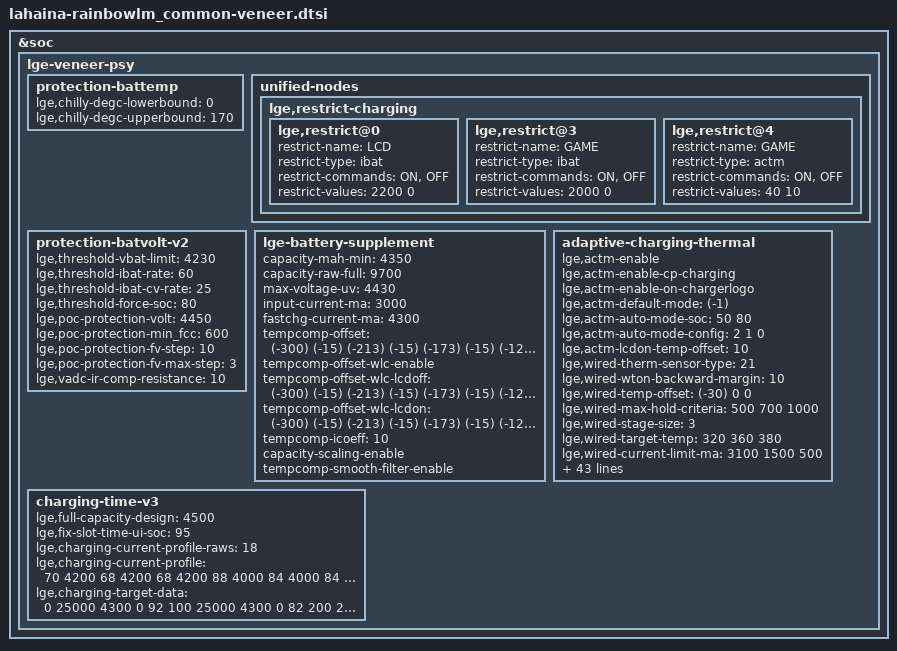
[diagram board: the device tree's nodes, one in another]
&soc {
	lge-veneer-psy {
		protection-battemp {
			lge,chilly-degc-lowerbound = <0>;
			lge,chilly-degc-upperbound = <170>;
		};

		unified-nodes {
			lge,restrict-charging {
				lge,restrict@0 {
					restrict-name = "LCD";
					restrict-type = "ibat";
					restrict-commands = "ON", "OFF";
					restrict-values = <2200      0>;
				};
				lge,restrict@3 {
					restrict-name = "GAME";
					restrict-type = "ibat";
					restrict-commands = "ON", "OFF";
					restrict-values = <2000      0>;
				};
				lge,restrict@4 {
					restrict-name = "GAME";
					restrict-type = "actm";
					restrict-commands = "ON", "OFF";
					restrict-values = <  40     10>;
				};
			};
		};

		/* it's for direct battery cell voltage sensing */
		protection-batvolt-v2 {
			lge,threshold-vbat-limit = <4230>;
			lge,threshold-ibat-rate = <60>;	// means 0.6C rate
			// the current to enter cv mode should be
			//			set to 600mA due to protection ic(4.45V).
			//			set to 1000mA due to protection ic(4.46V).
			lge,threshold-ibat-cv-rate = <25>;       // means 0.25C = 4350 * 0.23 = 1087mA
			lge,threshold-force-soc = <80>;          // %, set to 4.45V at ui soc 70%@ATL, 80%@LGC

			lge,poc-protection-volt = <4450>;
			lge,poc-protection-min_fcc = <600>;      // mA, fcc should be over cut-off current to enter termination.
			lge,poc-protection-fv-step = <10>;       // mV, if fcc is under min fcc, fv step down by 10mV.
			lge,poc-protection-fv-max-step = <3>;    // max count to step down.
			lge,vadc-ir-comp-resistance = <10>;       // mohm, compensated vadc for battery pack spec.
		};

		lge-battery-supplement {
			capacity-mah-min = <4350>;
			capacity-raw-full = <9700>;
			max-voltage-uv = <4430>;
			input-current-ma = <3000>;
			fastchg-current-ma = <4300>;

			/* format : (temp index) (temp delta) */
			tempcomp-offset = <
					(-300) (-15)
					(-213) (-15)
					(-173) (-15)
					(-126) (-15)
					( -75) (-12)
					( -23) (-12)
					( -10) (-13)
					27  (-12)
					73  (-15)
					117  (-10)
					162  (-9)
					208  (-9)
					254  (-8)
					303  (-7)
					354  (-8)
					408  (-8)
					461  (-8)
					512  (-8)
					561  (-8)
					608  (-8)
					647     4
					700     8
					730    12
					750    16
					800    20
			>;

			tempcomp-offset-wlc-enable;
			tempcomp-offset-wlc-lcdoff = <
					(-300) (-15)
					(-213) (-15)
					(-173) (-15)
					(-126) (-15)
					( -75) (-12)
					( -23) (-12)
					( -10) (-13)
					27  (-12)
					73  (-15)
					117  (-10)
					162  (-9)
					208  (-3)
					254     6
					303    30
					354    30
					408    38
					461    48
					512    11
					561    11
					608    11
					647     4
					700     8
					730    12
					750    16
					800    20
			>;

			tempcomp-offset-wlc-lcdon = <
					(-300) (-15)
					(-213) (-15)
					(-173) (-15)
					(-126) (-15)
					( -75) (-12)
					( -23) (-12)
					( -10) (-13)
					27  (-12)
					73  (-15)
					117  (-10)
					162  (-9)
					208  (-3)
					254     6
					303    30
					354    30
					408    38
					461    48
					512    11
					561    11
					608    11
					647     4
					700     8
					730    12
					750    16
					800    20
			>;

			tempcomp-icoeff = <10>;
			capacity-scaling-enable;
			tempcomp-smooth-filter-enable;
		};

		adaptive-charging-thermal {
			lge,actm-enable;
			lge,actm-enable-cp-charging;                    // whether cp charging is supported.
			lge,actm-enable-on-chargerlogo;                 // the actm operates charging first mode in chargerlogo
			lge,actm-default-mode = <(-1)>;                 // 0-thermal first, 1-balanced, 2-charging first, 3-auto
			/*  actm auto mode description
			 *                     48%            77%
			 *    2-charging first  |  1-balacned  |  0-thermal first */
			lge,actm-auto-mode-soc = <50 80>;               // those values are raw soc.
			lge,actm-auto-mode-config = <2 1 0>;            // <2 1 0> means actm mode
			lge,actm-lcdon-temp-offset = <10>;              // unit: 0.1 degree

			lge,wired-therm-sensor-type = <21>;             // bit(0)-BATT, bit(1)-VTS, Two Digit -> <$(LCDON)$(LCDOFF)>
			lge,wired-wton-backward-margin = <10>;          // temp margin when it transit from WARM to NORM.
			lge,wired-temp-offset = <(-30) 0 0>;            // thermal first, balanced, charging first
			lge,wired-max-hold-criteria = <500 700 1000>;   // allow rising 1 degree per 20/14/10/min
			lge,wired-stage-size = <3>;
			lge,wired-target-temp = <320 360 380>;
			lge,wired-current-limit-ma = <3100 1500 500>;   // 0-normal, 1-warm, 2-hot
			lge,wired-curr-cp-limit-ma = <4300 3200>;       // extension of lge,wired-current-limit-ma
			                                                // 0-normal & pps, 1-normal & qc3.0
			lge,wired-max-fcc-ma = <4300 3200 3100>;        // 0-pps ta, 1- qc3.0 ta, 2-qc2.0 ta
			lge,wired-current-step-size = <3>;
			lge,wired-current-step-temp = <5 15 30>;
			lge,wired-current-step-ma = <100 200 400>;
			lge,wired-timer-ms = <60000>;

			/* wired sidecar */
			lge,wired-sidecar-enable = <0 0 1>;             // <Thermal first, balanced, charging first>
			lge,wired-sidecar-therm-enter-temp = <380 400>;     // <LCD_OFF, LCD_ON>
			lge,wired-sidecar-therm-exit-temp = <370 390>;      // <LCD_OFF, LCD_ON>
			lge,wired-sidecar-therm-min-current = <1000 500>;   // <LCD_OFF, LCD_ON>
			lge,wired-sidecar-bal-enter-temp = <380 400>;       // <LCD_OFF, LCD_ON>
			lge,wired-sidecar-bal-exit-temp = <370 390>;        // <LCD_OFF, LCD_ON>
			lge,wired-sidecar-bal-min-current = <1000 500>;     // <LCD_OFF, LCD_ON>
			lge,wired-sidecar-chg-enter-temp = <380 400>;       // <LCD_OFF, LCD_ON>
			lge,wired-sidecar-chg-exit-temp = <370 390>;        // <LCD_OFF, LCD_ON>
			lge,wired-sidecar-chg-min-current = <1000 500>;     // <LCD_OFF, LCD_ON>

			lge,wireless-therm-sensor-type = <33>;          // bit(0)-BATT, bit(1)-VTS, Two Digit -> <$(LCDON)$(LCDOFF)>
			lge,wireless-wton-backward-margin = <0>;        // temp margin when it transit from WARM to NORM.
			lge,wireless-temp-offset = <(-30) 0 0>;         // thermal first, balanced, charging first
			lge,wireless-max-hold-criteria = <250 333 500>; // allow rising 1 degree per 40/30/20min
			lge,wireless-stage-size = <3>;
			lge,wireless-target-temp = <290 380 420>;
			lge,wireless-epp-power-limit-mw = <6300 4050 2750>;
			lge,wireless-bpp-power-limit-mw = <4400 3850 2750>;
			lge,wireless-15w-max-power-mw = <0 0 7200>; // <Thermal first, balanced, charging first>
			lge,wireless-power-step-size = <3>;
			lge,wireless-power-step-temp = <5 15 30>;
			lge,wireless-epp-power-step-mw = <450 900 1350>;
			lge,wireless-bpp-power-step-mw = <275 550 825>;
			lge,wireless-timer-ms = <60000>;

			/* wireless sidecar */
			lge,wireless-sidecar-enable = <0 0 1>;          // <Thermal first, balanced, charging first>
			lge,wireless-sidecar-therm-enter-temp = <420 420>;  // <LCD_OFF, LCD_ON>
			lge,wireless-sidecar-therm-exit-temp = <400 400>;   // <LCD_OFF, LCD_ON>
			lge,wireless-sidecar-therm-min-power = <3000 3000>; // <LCD_OFF, LCD_ON>
			lge,wireless-sidecar-bal-enter-temp = <420 420>;    // <LCD_OFF, LCD_ON>
			lge,wireless-sidecar-bal-exit-temp = <400 400>;     // <LCD_OFF, LCD_ON>
			lge,wireless-sidecar-bal-min-power = <3000 3000>;   // <LCD_OFF, LCD_ON>
			lge,wireless-sidecar-chg-enter-temp = <420 420>;    // <LCD_OFF, LCD_ON>
			lge,wireless-sidecar-chg-exit-temp = <400 400>;     // <LCD_OFF, LCD_ON>
			lge,wireless-sidecar-chg-min-power = <3000 3000>;   // <LCD_OFF, LCD_ON>
		};

		charging-time-v3 {
			lge,full-capacity-design = <4500>;
			lge,fix-slot-time-ui-soc = <95>;

			lge,charging-current-profile-raws = <18>;  /* max: 20 */
			lge,charging-current-profile = <
			/* format: raw_soc, raw_current(mA) */
			/* | Thermal |  | Balanced | | Charging | */
				 70  4200     68  4200     68  4200
				 88  4000     84  4000     84  4000
				137  3800    133  3800    133  3800
				142  3600    138  3600    138  3600
				152  3200    146  3200    146  3200
				160  3000    154  3000    154  3000
				165  2800    159  2800    159  2800
				170  2600    164  2600    164  2600
				208  2500    201  2500    201  2500
				211  2300    205  2300    205  2300
				216  2100    209  2100    209  2100
				221  1900    214  1900    214  1900
				226  1700    220  1700    220  1700
				234  1500    227  1500    227  1500
				241  1300    233  1300    233  1300
				246  1100    240  1100    240  1100
				254   900    245   900    245   900
				255   700    246   700    246   700   /* <- END -> */
			>;

			lge,charging-target-data = <
	/* format : type, power(mW), current(mA), down(uA), target(min) */
	/* cp pps  thermal  */    0    25000    4300       0     92
	/*         balanced */  100    25000    4300       0     82
	/*         charging */  200    25000    4300       0     82
	/* CP QC3  thermal  */    1    16200    3200       0    100
	/*         balanced */  101    16200    3200       0     90
	/*         charging */  201    16200    3200       0     90
	/* QC2     thermal  */    2    15000    3100       0    100
	/*         balanced */  102    15000    3100       0     90
	/*         charging */  202    15000    3100       0     90
	/* DCP     thermal  */    2     7500    1650     881    160
	/*         balanced */  102     7500    1650     881    160
	/*         charging */  202     7500    1650     881    160
	/* SDP     thermal  */    2     2500     500       0    500
	/*         balanced */  102     2500     500       0    500
	/*         charging */  202     2500     500       0    500
	/* WLC EPP thermal  */    3     7200    1750    2224    230
	/*         balanced */  103     7200    1750    2224    210
	/*         charging */  203     7200    1750    1032    210
	/* WLC BPP thermal  */    3     4500    1100     920    280
	/*         balanced */  103     4500    1100     920    260
	/*         charging */  203     4500    1100     640    260
	/* BCC     thermal  */    4    12500    2000       0    125
	/*         balanced */  104    12500    2000       0    125
	/*         charging */  204    12500    2000       0    125
			>;
		};
	};
};
